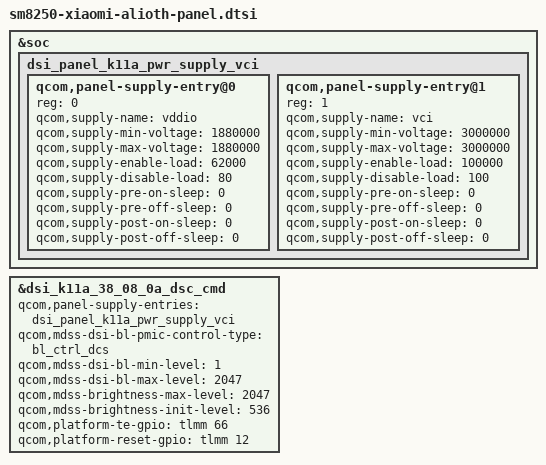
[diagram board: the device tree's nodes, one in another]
// SPDX-License-Identifier: GPL-2.0-only
/* K11A commands, GPIOs and supply sequencing from the donor. */
#include "dsi-panel-k11a-38-08-0a-dsc-cmd.dtsi"

&soc {
	dsi_panel_k11a_pwr_supply_vci: dsi_panel_k11a_pwr_supply_vci {
	#address-cells = <1>;
	#size-cells = <0>;

		qcom,panel-supply-entry@0 {
			reg = <0>;
			qcom,supply-name = "vddio";
			qcom,supply-min-voltage = <1880000>;
			qcom,supply-max-voltage = <1880000>;
			qcom,supply-enable-load = <62000>;
			qcom,supply-disable-load = <80>;
			qcom,supply-pre-on-sleep = <0>;
			qcom,supply-pre-off-sleep = <0>;
			qcom,supply-post-on-sleep = <0>;
			qcom,supply-post-off-sleep = <0>;
		};

		qcom,panel-supply-entry@1 {
			reg = <1>;
			qcom,supply-name = "vci";
			qcom,supply-min-voltage = <3000000>;
			qcom,supply-max-voltage = <3000000>;
			qcom,supply-enable-load = <100000>;
			qcom,supply-disable-load = <100>;
			qcom,supply-pre-on-sleep = <0>;
			qcom,supply-pre-off-sleep = <0>;
			qcom,supply-post-on-sleep = <0>;
			qcom,supply-post-off-sleep = <0>;
		};
	};
};

&dsi_k11a_38_08_0a_dsc_cmd {
        qcom,panel-supply-entries = <&dsi_panel_k11a_pwr_supply_vci>;
        qcom,mdss-dsi-bl-pmic-control-type = "bl_ctrl_dcs";
        qcom,mdss-dsi-bl-min-level = <1>;
        qcom,mdss-dsi-bl-max-level = <2047>;
        qcom,mdss-brightness-max-level = <2047>;
        qcom,mdss-brightness-init-level = <536>;
        qcom,platform-te-gpio = <&tlmm 66 0>;
        qcom,platform-reset-gpio = <&tlmm 12 0>;
};
